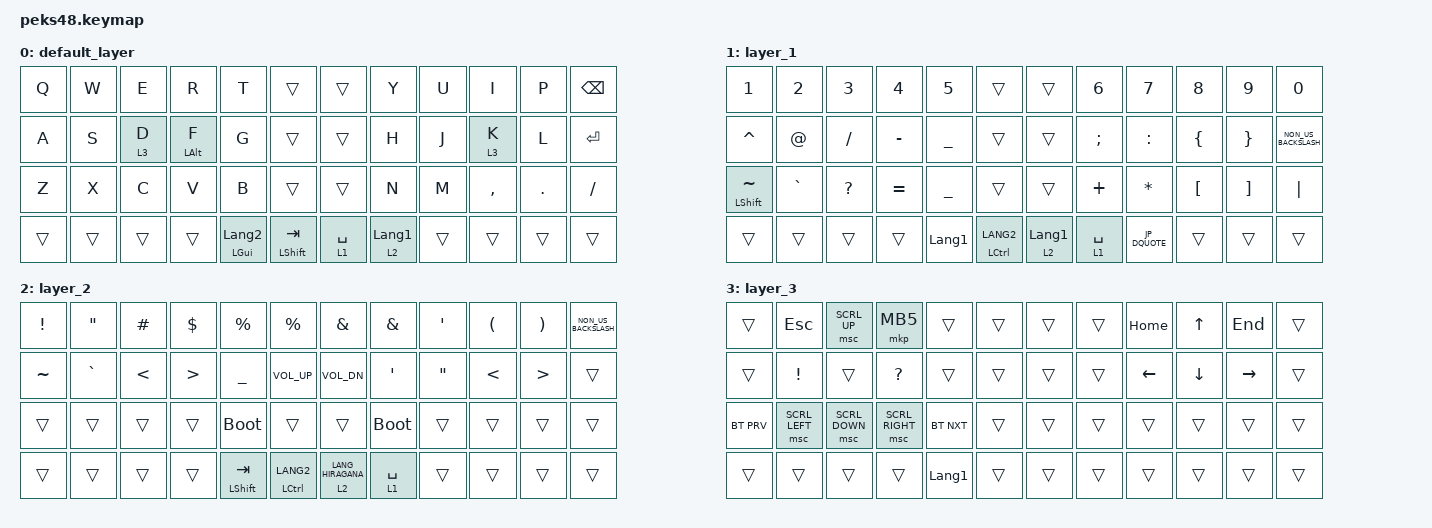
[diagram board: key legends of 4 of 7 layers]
#include <input/processors.dtsi>
#include <dt-bindings/zmk/input_transform.h>
#include <zephyr/dt-bindings/input/input-event-codes.h>
#include <behaviors.dtsi>
#include <dt-bindings/zmk/bt.h>
#include <dt-bindings/zmk/keys.h>
#include <dt-bindings/zmk/pointing.h>

// Conversion definition for using Japanese keyboard with OS settings

#define JP_DQUOTE       AT                // "
#define JP_AMPERSAND    CARET             // &
#define JP_QUOTE        AMPERSAND         // '
#define JP_EQUAL        UNDER             // =
#define JP_CARET        EQUAL             // ^
#define JP_YEN          0x89              // ¥
#define JP_PLUS         COLON             // +
#define JP_TILDE        PLUS              // ~
#define JP_PIPE         LS(0x89)          // |
#define JP_AT           LEFT_BRACKET      // @
#define JP_COLON        SINGLE_QUOTE      // :
#define JP_ASTERISK     DOUBLE_QUOTES     // *
#define JP_BACKQUOTE    LEFT_BRACE        // `
#define JP_UNDERSCORE   LS(0x87)          // _
#define JP_LBRACKET     RIGHT_BRACKET     // [
#define JP_RBRACKET     BACKSLASH         // ]
#define JP_LPAREN       ASTERISK          // (
#define JP_RPAREN       LEFT_PARENTHESIS  // )
#define JP_LBRACE       RIGHT_BRACE       // {
#define JP_RBRACE       PIPE              // }
#define JP_KANA         LANGUAGE_1        // かな
#define JP_EISU         LANGUAGE_2        // 英数
#define JP_HANZEN       GRAVE             // 半角/全角

&mt {
    flavor = "balanced";
    quick-tap-ms = <0>;
};

/ {
    keymap {
        compatible = "zmk,keymap";

        default_layer {
            bindings = <
&kp Q   &kp W   &kp E    &kp R           &kp T                    &trans                &trans       &kp Y             &kp U   &kp I      &kp P       &kp BACKSPACE
&kp A   &kp S   &lt 3 D  &mt LEFT_ALT F  &kp G                    &trans                &trans       &kp H             &kp J   &lt 3 K    &kp L       &kp ENTER
&kp Z   &kp X   &kp C    &kp V           &kp B                    &trans                &trans       &kp N             &kp M   &kp COMMA  &kp PERIOD  &kp SLASH
&trans  &trans  &trans   &trans          &mt LEFT_GUI LANGUAGE_2  &mt LEFT_SHIFT TAB    &lt 1 SPACE  &lt 2 LANGUAGE_1  &trans  &trans     &trans      &trans
            >;
        };

        layer_1 {
            bindings = <
&kp NUMBER_1          &kp NUMBER_2  &kp NUMBER_3  &kp NUMBER_4  &kp N5          &trans             &trans            &kp NUMBER_6   &kp NUMBER_7   &kp NUMBER_8      &kp NUMBER_9       &kp NUMBER_0
&kp CARET             &kp AT_SIGN   &kp SLASH     &kp MINUS     &kp UNDERSCORE  &trans             &trans            &kp SEMICOLON  &kp COLON      &kp LEFT_BRACE    &kp RIGHT_BRACE    &kp NON_US_BACKSLASH
&mt LEFT_SHIFT TILDE  &kp GRAVE     &kp QUESTION  &kp EQUAL     &kp UNDER       &trans             &trans            &kp PLUS       &kp ASTERISK   &kp LEFT_BRACKET  &kp RIGHT_BRACKET  &kp PIPE
&trans                &trans        &trans        &trans        &kp LANGUAGE_1  &mt LCTRL LANG2    &lt 2 LANGUAGE_1  &lt 1 SPACE    &kp JP_DQUOTE  &trans            &trans             &trans
            >;
        };

        layer_2 {
            bindings = <
&kp EXCLAMATION  &kp DOUBLE_QUOTES  &kp HASH       &kp DOLLAR        &kp PERCENT         &kp PERCENT        &kp AMPERSAND        &kp AMPERSAND  &kp SQT            &kp LEFT_PARENTHESIS  &kp RIGHT_PARENTHESIS  &kp NON_US_BACKSLASH
&kp TILDE        &kp GRAVE          &kp LESS_THAN  &kp GREATER_THAN  &kp UNDERSCORE      &kp C_VOL_UP       &kp C_VOL_DN         &kp SQT        &kp DOUBLE_QUOTES  &kp LESS_THAN         &kp GREATER_THAN       &trans
&trans           &trans             &trans         &trans            &bootloader         &trans             &trans               &bootloader    &trans             &trans                &trans                 &trans
&trans           &trans             &trans         &trans            &mt LEFT_SHIFT TAB  &mt LCTRL LANG2    &lt 2 LANG_HIRAGANA  &lt 1 SPACE    &trans             &trans                &trans                 &trans
            >;
        };

        layer_3 {
            bindings = <
&trans      &kp ESC          &msc SCRL_UP    &mkp MB5         &trans          &trans    &trans  &trans  &kp HOME  &kp UP_ARROW    &kp END    &trans
&trans      &kp EXCLAMATION  &trans          &kp QUESTION     &trans          &trans    &trans  &trans  &kp LEFT  &kp DOWN_ARROW  &kp RIGHT  &trans
&bt BT_PRV  &msc SCRL_LEFT   &msc SCRL_DOWN  &msc SCRL_RIGHT  &bt BT_NXT      &trans    &trans  &trans  &trans    &trans          &trans     &trans
&trans      &trans           &trans          &trans           &kp LANGUAGE_1  &trans    &trans  &trans  &trans    &trans          &trans     &trans
            >;
        };

        layer_4 {
            bindings = <
&trans  &trans  &trans  &trans  &trans  &trans    &trans       &bt BT_SEL 0  &bt BT_SEL 1  &bt BT_SEL 2  &bt BT_SEL 3  &bt BT_SEL 4
&trans  &trans  &trans  &trans  &trans  &trans    &trans       &tog 6        &trans        &trans        &trans        &bt BT_CLR
&trans  &trans  &trans  &trans  &trans  &trans    &bootloader  &trans        &trans        &trans        &trans        &bt BT_CLR_ALL
&trans  &trans  &trans  &trans
            >;
        };

        layer_5 {
            bindings = <
&trans  &trans  &trans    &trans    &trans    &trans    &trans  &trans    &trans    &trans    &trans  &trans
&trans  &trans  &mkp MB3  &mkp MB2  &mkp MB1  &trans    &trans  &mkp MB1  &mkp MB2  &mkp MB3  &trans  &trans
&trans  &trans  &trans    &trans    &trans    &trans    &trans  &trans    &trans    &trans    &trans  &trans
&trans  &trans  &trans    &trans
            >;
        };

        layer_6 {
            bindings = <
&trans  &trans  &trans  &trans  &trans  &trans    &trans  &trans  &trans    &trans    &trans    &trans
&trans  &trans  &trans  &trans  &trans  &trans    &trans  &trans  &mkp MB1  &mkp MB3  &mkp MB2  &trans
&trans  &trans  &trans  &trans  &trans  &trans    &trans  &trans  &trans    &trans    &trans    &trans
&trans  &trans  &trans  &trans
            >;
        };
    };
};
